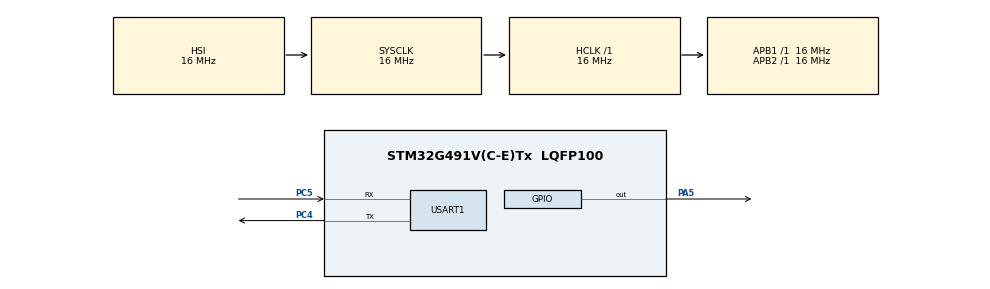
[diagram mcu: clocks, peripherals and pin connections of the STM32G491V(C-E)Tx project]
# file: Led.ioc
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Dma.Request0=USART1_TX
Dma.USART1_TX.0.Direction=DMA_MEMORY_TO_PERIPH
Dma.USART1_TX.0.EventEnable=DISABLE
Dma.USART1_TX.0.Instance=DMA1_Channel1
Dma.USART1_TX.0.MemDataAlignment=DMA_MDATAALIGN_BYTE
Dma.USART1_TX.0.MemInc=DMA_MINC_ENABLE
Dma.USART1_TX.0.Mode=DMA_NORMAL
Dma.USART1_TX.0.PeriphDataAlignment=DMA_PDATAALIGN_BYTE
Dma.USART1_TX.0.PeriphInc=DMA_PINC_DISABLE
Dma.USART1_TX.0.Polarity=HAL_DMAMUX_REQ_GEN_RISING
Dma.USART1_TX.0.Priority=DMA_PRIORITY_LOW
Dma.USART1_TX.0.RequestNumber=1
Dma.USART1_TX.0.SignalID=NONE
Dma.USART1_TX.0.SyncEnable=DISABLE
Dma.USART1_TX.0.SyncPolarity=HAL_DMAMUX_SYNC_NO_EVENT
Dma.USART1_TX.0.SyncRequestNumber=1
Dma.USART1_TX.0.SyncSignalID=NONE
Mcu.Family=STM32G4
Mcu.Name=STM32G491V(C-E)Tx
Mcu.Package=LQFP100
NVIC.DMA1_Channel1_IRQn=true\:0\:0\:false\:false\:true\:false\:true\:true
NVIC.PriorityGroup=NVIC_PRIORITYGROUP_4
NVIC.TIM2_IRQn=true\:0\:0\:false\:false\:true\:true\:true\:true
NVIC.TIM6_DAC_IRQn=true\:15\:0\:false\:false\:true\:false\:true\:true
NVIC.TimeBase=TIM6_DAC_IRQn
NVIC.TimeBaseIP=TIM6
NVIC.USART1_IRQn=true\:0\:0\:false\:false\:true\:true\:true\:true
PA13.Mode=Serial_Wire
PA13.Signal=SYS_JTMS-SWDIO
PA14.Mode=Serial_Wire
PA14.Signal=SYS_JTCK-SWCLK
PA5.Signal=GPIO_Output
PC4.Mode=Asynchronous
PC4.Signal=USART1_TX
PC5.Mode=Asynchronous
PC5.Signal=USART1_RX
ProjectManager.HeapSize=0x200
ProjectManager.StackSize=0x400
ProjectManager.TargetToolchain=STM32CubeIDE
RCC.ADC12Freq_Value=16000000
RCC.ADC345Freq_Value=16000000
RCC.AHBFreq_Value=16000000
RCC.APB1Freq_Value=16000000
RCC.APB1TimFreq_Value=16000000
RCC.APB2Freq_Value=16000000
RCC.APB2TimFreq_Value=16000000
RCC.CortexFreq_Value=16000000
RCC.EXTERNAL_CLOCK_VALUE=12288000
RCC.HCLKFreq_Value=16000000
RCC.HSE_VALUE=8000000
RCC.HSI48_VALUE=48000000
RCC.HSI_VALUE=16000000
RCC.LSE_VALUE=32768
RCC.SYSCLKFreq_VALUE=16000000
RCC.VCOOutputFreq_Value=128000000
TIM2.PeriodNoDither=499
TIM2.Prescaler=15999
TIM2.TIM_MasterOutputTrigger=TIM_TRGO_UPDATE
USART1.VirtualMode-Asynchronous=VM_ASYNC
VP_SYS_VS_DBSignals.Mode=DisableDeadBatterySignals
VP_SYS_VS_tim6.Mode=TIM6
VP_TIM1_VS_ClockSourceINT.Mode=Internal
VP_TIM2_VS_ClockSourceINT.Mode=Internal
board=custom

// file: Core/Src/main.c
/* USER CODE BEGIN Header */
/**
  ******************************************************************************
  * @file           : main.c
  * @brief          : Main program body
  ******************************************************************************
  * @attention
  *
  * Copyright (c) 2026 STMicroelectronics.
  * All rights reserved.
  *
  * This software is licensed under terms that can be found in the LICENSE file
  * in the root directory of this software component.
  * If no LICENSE file comes with this software, it is provided AS-IS.
  *
  ******************************************************************************
  */
/* USER CODE END Header */
#include "main.h"
#include "dma.h"
#include "tim.h"
#include "usart.h"
#include "gpio.h"

/* USER CODE BEGIN Includes */
#include "BoardManagerWrapper.h"
#include <stdio.h>
#include <string.h>
#include <math.h>
#include "ring_buffer.h"
#include "FreeRTOS.h"
#include "task.h"
#include "queue.h"
#include "semphr.h"
#include "trcRecorder.h"
/* USER CODE END Includes */

/* USER CODE BEGIN PV */
  extern ring_buffer rb;
  extern uint8_t buf[200];

  /* Exercise 3: watch these in the debugger */
  static TaskHandle_t exSleeper;
  static TaskHandle_t exSpinner;
  static volatile uint32_t exSleeperRuns;    /* times the sleeper got to run its loop */
  static volatile uint32_t exSleeperTick;    /* tick count the last time it ran */
  static volatile uint32_t exSpinnerLoops;   /* spinner busy-loop counter */

  /* Exercise 3 user events (Tracealyzer channel "ex3") */
  static TraceStringHandle_t exChannel;
  static TraceStringHandle_t exFmtHandles, exFmtRun;

/* USER CODE END PV */

void SystemClock_Config(void);

/* USER CODE BEGIN 0 */

/*
 * Exercise 3: two tasks at the same priority, with preemption on and time
 * slicing off (configUSE_TIME_SLICING 0 in FreeRTOSConfig.h).
 *
 * The sleeper creates the spinner, then loops on vTaskDelay(). The spinner
 * never blocks.
 *
 * Expected: with time slicing off, an equal-priority task never takes the CPU
 * away from the running one, so once the spinner is running the sleeper
 * should never run again. exSleeperRuns should stay at 1.
 * Compare that with what you observe.
 */
static void exSpinnerTask(void *arg)
{
  (void)arg;
  for (;;)
  {
    exSpinnerLoops++;
  }
}

static void exSleeperTask(void *arg)
{
  (void)arg;

  xTaskCreate(exSpinnerTask, "exSpin", 256, NULL, 2, &exSpinner);
  xTracePrintF2(exChannel, exFmtHandles,
                (TraceUnsignedBaseType_t)exSleeper, (TraceUnsignedBaseType_t)exSpinner);

  for (;;)
  {
    exSleeperRuns++;
    exSleeperTick = xTaskGetTickCount();
    xTracePrintF2(exChannel, exFmtRun, exSleeperRuns, exSleeperTick);
    printf("sleeper: run #%lu at tick %lu\r\n",
           (unsigned long)exSleeperRuns, (unsigned long)exSleeperTick);
    vTaskDelay(pdMS_TO_TICKS(500));
  }
}

/* USER CODE END 0 */

int main(void)
{

  /* MCU Configuration--------------------------------------------------------*/

  /* Reset of all peripherals, Initializes the Flash interface and the Systick. */
  HAL_Init();

  /* Configure the system clock */
  SystemClock_Config();

  /* Initialize all configured peripherals */
  MX_GPIO_Init();
  MX_DMA_Init();
  MX_TIM2_Init();
  MX_USART1_UART_Init();
  MX_TIM1_Init();
  /* USER CODE BEGIN 2 */
  xTraceEnable(TRC_START);

  rb_create(&rb, buf, 200);

  /* enable the DWT cycle counter (16 cyc = 1 us at 16 MHz) */
  CoreDebug->DEMCR |= CoreDebug_DEMCR_TRCENA_Msk;
  DWT->CTRL        |= DWT_CTRL_CYCCNTENA_Msk;

  xTraceStringRegister("ex3", &exChannel);
  xTraceStringRegister("sleeper handle=0x%X spinner handle=0x%X", &exFmtHandles);
  xTraceStringRegister("sleeper run #%u at tick %u", &exFmtRun);

  /* only the sleeper is created here; it creates the spinner itself */
  xTaskCreate(exSleeperTask, "exSleep", 256, NULL, 2, &exSleeper);
  vTaskStartScheduler();

  /* USER CODE END 2 */

  /* Infinite loop */
  while (1)
  {
  }

}

void SystemClock_Config(void)
{
  RCC_OscInitTypeDef RCC_OscInitStruct = {0};
  RCC_ClkInitTypeDef RCC_ClkInitStruct = {0};

  /** Configure the main internal regulator output voltage
  */
  HAL_PWREx_ControlVoltageScaling(PWR_REGULATOR_VOLTAGE_SCALE1);

  /** Initializes the RCC Oscillators according to the specified parameters
  * in the RCC_OscInitTypeDef structure.
  */
  RCC_OscInitStruct.OscillatorType = RCC_OSCILLATORTYPE_HSI;
  RCC_OscInitStruct.HSIState = RCC_HSI_ON;
  RCC_OscInitStruct.HSICalibrationValue = RCC_HSICALIBRATION_DEFAULT;
  RCC_OscInitStruct.PLL.PLLState = RCC_PLL_NONE;
  if (HAL_RCC_OscConfig(&RCC_OscInitStruct) != HAL_OK)
  {
    Error_Handler();
  }

  /** Initializes the CPU, AHB and APB buses clocks
  */
  RCC_ClkInitStruct.ClockType = RCC_CLOCKTYPE_HCLK|RCC_CLOCKTYPE_SYSCLK
                              |RCC_CLOCKTYPE_PCLK1|RCC_CLOCKTYPE_PCLK2;
  RCC_ClkInitStruct.SYSCLKSource = RCC_SYSCLKSOURCE_HSI;
  RCC_ClkInitStruct.AHBCLKDivider = RCC_SYSCLK_DIV1;
  RCC_ClkInitStruct.APB1CLKDivider = RCC_HCLK_DIV1;
  RCC_ClkInitStruct.APB2CLKDivider = RCC_HCLK_DIV1;

  if (HAL_RCC_ClockConfig(&RCC_ClkInitStruct, FLASH_LATENCY_0) != HAL_OK)
  {
    Error_Handler();
  }
}

void HAL_TIM_PeriodElapsedCallback(TIM_HandleTypeDef *htim)
{
  if (htim->Instance == TIM6)
  {
    HAL_IncTick();
  }
}

void Error_Handler(void)
{
  __disable_irq();
  while (1)
  {
  }
}

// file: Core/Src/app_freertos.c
/* USER CODE BEGIN Header */
/**
  ******************************************************************************
  * File Name          : app_freertos.c
  * Description        : Code for freertos applications
  ******************************************************************************
  * @attention
  *
  * Copyright (c) 2026 STMicroelectronics.
  * All rights reserved.
  *
  * This software is licensed under terms that can be found in the LICENSE file
  * in the root directory of this software component.
  * If no LICENSE file comes with this software, it is provided AS-IS.
  *
  ******************************************************************************
  */
/* USER CODE END Header */

#include "FreeRTOS.h"
#include "task.h"
#include "main.h"
#include "cmsis_os.h"

/* USER CODE BEGIN Includes */
#include "BoardManagerWrapper.h"
#include "adc.h"
#include "tim.h"

/* USER CODE END Includes */

/* USER CODE BEGIN PD */
volatile uint32_t isr_cycle = 0;
volatile uint32_t task_cycle = 0;
volatile uint32_t latency_cycles = 0;

/* USER CODE END PD */

/* USER CODE BEGIN PM */
#define BUF_SIZE			3u

/* USER CODE END PM */

/* USER CODE BEGIN Variables */
extern void* bm;
extern volatile uint16_t adc_buf[3];

/* USER CODE END Variables */
osThreadId defaultTaskHandle;
osThreadId myTask02Handle;
osThreadId myTask03Handle;
osMutexId uartHandle;
osSemaphoreId adc_readyHandle;

/* USER CODE BEGIN FunctionPrototypes */
uint32_t buf[BUF_SIZE]={0};
uint8_t index_ptr=0;
uint8_t num=0;

/* USER CODE END FunctionPrototypes */

void low_priority(void const * argument);
void adc_task(void const * argument);
void slow(void const * argument);

void MX_FREERTOS_Init(void); /* (MISRA C 2004 rule 8.1) */

/* Hook prototypes */
void vApplicationStackOverflowHook(xTaskHandle xTask, signed char *pcTaskName);
void vApplicationMallocFailedHook(void);

/* USER CODE BEGIN 4 */
__weak void vApplicationStackOverflowHook(xTaskHandle xTask, signed char *pcTaskName)
{
	volatile xTaskHandle bad_task_handle = xTask;
	volatile char* bad_task = pcTaskName;
	while (1){
		__NOP();
	}

   /* Run time stack overflow checking is performed if
   configCHECK_FOR_STACK_OVERFLOW is defined to 1 or 2. This hook function is
   called if a stack overflow is detected. */
}
/* USER CODE END 4 */

/* USER CODE BEGIN 5 */
__weak void vApplicationMallocFailedHook(void)
{
   /* vApplicationMallocFailedHook() will only be called if
   configUSE_MALLOC_FAILED_HOOK is set to 1 in FreeRTOSConfig.h. It is a hook
   function that will get called if a call to pvPortMalloc() fails.
   pvPortMalloc() is called internally by the kernel whenever a task, queue,
   timer or semaphore is created. It is also called by various parts of the
   demo application. If heap_1.c or heap_2.c are used, then the size of the
   heap available to pvPortMalloc() is defined by configTOTAL_HEAP_SIZE in
   FreeRTOSConfig.h, and the xPortGetFreeHeapSize() API function can be used
   to query the size of free heap space that remains (although it does not
   provide information on how the remaining heap might be fragmented). */
	while (1){__NOP();}
}
/* USER CODE END 5 */

void MX_FREERTOS_Init(void) {
  /* Create the mutex(es) */
  /* definition and creation of uart */
  osMutexDef(uart);
  uartHandle = osMutexCreate(osMutex(uart));

  /* Create the semaphores(s) */
  /* definition and creation of adc_ready */
  osSemaphoreDef(adc_ready);
  adc_readyHandle = osSemaphoreCreate(osSemaphore(adc_ready), 1);

  /* USER CODE BEGIN RTOS_SEMAPHORES */
  osSemaphoreWait(adc_readyHandle, 0);
  /* USER CODE END RTOS_SEMAPHORES */

  /* Create the thread(s) */
  /* definition and creation of defaultTask */
  osThreadDef(defaultTask, low_priority, osPriorityNormal, 0, 512);
  defaultTaskHandle = osThreadCreate(osThread(defaultTask), NULL);

  /* definition and creation of myTask02 */
  osThreadDef(myTask02, adc_task, osPriorityHigh, 0, 1024);
  myTask02Handle = osThreadCreate(osThread(myTask02), NULL);

  /* definition and creation of myTask03 */
  osThreadDef(myTask03, slow, osPriorityAboveNormal, 0, 512);
  myTask03Handle = osThreadCreate(osThread(myTask03), NULL);

}

void low_priority(void const * argument)
{
  /* USER CODE BEGIN low_priority */
	//default task
  /* Infinite loop */
  for(;;)
  {
  osDelay(1);

  osMutexWait(uartHandle, osWaitForever);
  printf("low takes mutex at %ld\r\n", HAL_GetTick());
  osDelay(100);
  low_priority_task();
  printf("low returns mutex at %ld\r\n", HAL_GetTick());
  osMutexRelease(uartHandle);
  printf("stack size: %ld\r\n", (unsigned long) uxTaskGetStackHighWaterMark(NULL)*4);

  }
  /* USER CODE END low_priority */
}

void adc_task(void const * argument)
{
  /* USER CODE BEGIN adc_task */
	//mytask02
  HAL_ADC_Start_DMA(&hadc1, (uint32_t*) adc_buf, 3);
  HAL_TIM_Base_Start(&htim2);

  /* Infinite loop */
  for(;;)
  {

  osSemaphoreWait(adc_readyHandle, osWaitForever);
  task_cycle = DWT->CYCCNT;
  latency_cycles = task_cycle - isr_cycle;
  buf[index_ptr] = latency_cycles;
  index_ptr = (index_ptr+1) % BUF_SIZE;

  uint64_t sum=0;
  for (uint8_t i = 0; i < BUF_SIZE; i++){
	  sum = sum + buf[i];
  }

  if (num < BUF_SIZE){
	  num++;
  }

  uint32_t avg = sum / num;

  printf("\r\n\r\ncpu cycles: %lu\r\n\r\n", avg);
  osDelay(500);
  osMutexWait(uartHandle, osWaitForever);

  printf("high takes at %ld\r\n", HAL_GetTick());
  bm_adc(bm);
  osDelay(50);
  printf("high returns at %ld\r\n", HAL_GetTick());
  osMutexRelease(uartHandle);
  printf("stack size: %ld bytes\r\n", (unsigned long) uxTaskGetStackHighWaterMark(NULL)*4);
  //HAL_Delay(2000);
  }
  /* USER CODE END adc_task */
}

void slow(void const * argument)
{
  /* USER CODE BEGIN slow */
	//mytask03
  /* Infinite loop */
  for(;;)
  {
  osDelay(15);
  printf("reach slow at %ld\r\n", HAL_GetTick());
  HAL_Delay(300);
  printf("stack size: %ld\r\n", (unsigned long) uxTaskGetStackHighWaterMark(NULL)*4);

  }
  /* USER CODE END slow */
}

/* USER CODE BEGIN Application */
void HAL_ADC_ConvCpltCallback(ADC_HandleTypeDef *hadc){

	if (hadc->Instance == ADC1){
		//adc_ready=1;
		isr_cycle = DWT->CYCCNT;
		osSemaphoreRelease(adc_readyHandle);

	}
}

/* USER CODE END Application */
